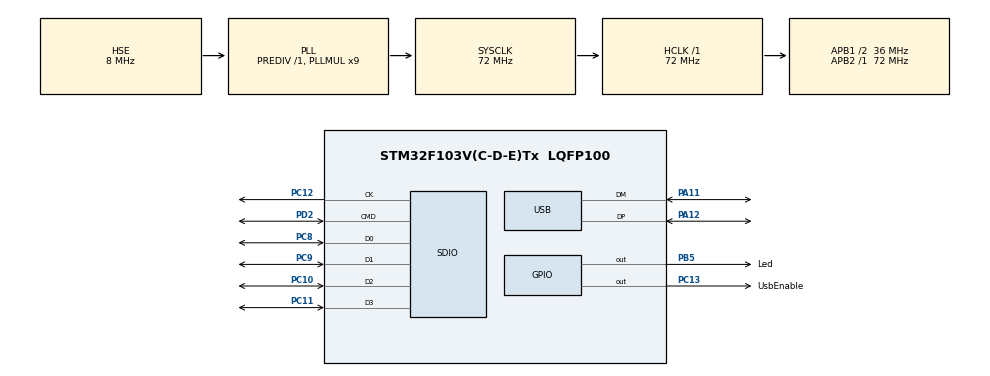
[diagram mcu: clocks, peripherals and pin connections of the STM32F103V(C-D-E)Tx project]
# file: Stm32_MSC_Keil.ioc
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Mcu.Family=STM32F1
Mcu.Name=STM32F103V(C-D-E)Tx
Mcu.Package=LQFP100
NVIC.PriorityGroup=NVIC_PRIORITYGROUP_4
NVIC.TIM1_UP_IRQn=true\:0\:0\:false\:false\:true\:false\:true
NVIC.TimeBase=TIM1_UP_IRQn
NVIC.TimeBaseIP=TIM1
NVIC.USB_LP_CAN1_RX0_IRQn=true\:0\:0\:false\:false\:true\:false\:true
OSC_IN.Mode=HSE-External-Oscillator
OSC_IN.Signal=RCC_OSC_IN
OSC_OUT.Mode=HSE-External-Oscillator
OSC_OUT.Signal=RCC_OSC_OUT
PA11.Mode=Device
PA11.Signal=USB_DM
PA12.Mode=Device
PA12.Signal=USB_DP
PB5.GPIO_Label=Led
PB5.Signal=GPIO_Output
PC10.Mode=SD_4_bits_Wide_bus
PC10.Signal=SDIO_D2
PC11.Mode=SD_4_bits_Wide_bus
PC11.Signal=SDIO_D3
PC12.Mode=SD_4_bits_Wide_bus
PC12.Signal=SDIO_CK
PC13-TAMPER-RTC.GPIO_Label=UsbEnable
PC13-TAMPER-RTC.Signal=GPIO_Output
PC14-OSC32_IN.Mode=LSE-External-Oscillator
PC14-OSC32_IN.Signal=RCC_OSC32_IN
PC15-OSC32_OUT.Mode=LSE-External-Oscillator
PC15-OSC32_OUT.Signal=RCC_OSC32_OUT
PC8.Mode=SD_4_bits_Wide_bus
PC8.Signal=SDIO_D0
PC9.Mode=SD_4_bits_Wide_bus
PC9.Signal=SDIO_D1
PD2.Mode=SD_4_bits_Wide_bus
PD2.Signal=SDIO_CMD
ProjectManager.HeapSize=0x2000
ProjectManager.StackSize=0x4000
ProjectManager.TargetToolchain=MDK-ARM V5
RCC.AHBFreq_Value=72000000
RCC.APB1CLKDivider=RCC_HCLK_DIV2
RCC.APB1Freq_Value=36000000
RCC.APB1TimFreq_Value=72000000
RCC.APB2Freq_Value=72000000
RCC.APB2TimFreq_Value=72000000
RCC.HCLKFreq_Value=72000000
RCC.PLLMUL=RCC_PLL_MUL9
RCC.SYSCLKFreq_VALUE=72000000
RCC.SYSCLKSource=RCC_SYSCLKSOURCE_PLLCLK
RCC.USBFreq_Value=48000000
RCC.USBPrescaler=RCC_USBCLKSOURCE_PLL_DIV1_5
SDIO.ClockDiv=4
USB_DEVICE.CLASS_NAME_FS=MSC
USB_DEVICE.VirtualMode=Msc
USB_DEVICE.VirtualModeFS=Msc_FS
VP_FATFS_VS_SDIO.Mode=SDIO
VP_SYS_VS_ND.Mode=No_Debug
VP_SYS_VS_tim1.Mode=TIM1
VP_USB_DEVICE_VS_USB_DEVICE_MSC_FS.Mode=MSC_FS
board=custom

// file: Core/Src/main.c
/* USER CODE BEGIN Header */
/**
  ******************************************************************************
  * @file           : main.c
  * @brief          : Main program body
  ******************************************************************************
  * @attention
  *
  * <h2><center>&copy; Copyright (c) 2019 STMicroelectronics.
  * All rights reserved.</center></h2>
  *
  * This software component is licensed by ST under Ultimate Liberty license
  * SLA0044, the "License"; You may not use this file except in compliance with
  * the License. You may obtain a copy of the License at:
  *                             www.st.com/SLA0044
  *
  ******************************************************************************
  */
/* USER CODE END Header */

#include "main.h"
#include "fatfs.h"
#include "sdio.h"
#include "usb_device.h"
#include "gpio.h"

void SystemClock_Config(void);

int main(void)
{

  /* MCU Configuration--------------------------------------------------------*/

  /* Reset of all peripherals, Initializes the Flash interface and the Systick. */
  HAL_Init();

  /* Configure the system clock */
  SystemClock_Config();

  /* Initialize all configured peripherals */
  MX_GPIO_Init();
  MX_SDIO_SD_Init();
  MX_FATFS_Init();
  MX_USB_DEVICE_Init();
  /* USER CODE BEGIN 2 */
	//if (SD_IAPUpdateReq()) {
	  //HAL_GPIO_WritePin(Led_GPIO_Port, Led_Pin, GPIO_PIN_SET);
	//}
  /* USER CODE END 2 */

  /* Infinite loop */
  while (1)
  {

  }
}

void SystemClock_Config(void)
{
  RCC_OscInitTypeDef RCC_OscInitStruct = {0};
  RCC_ClkInitTypeDef RCC_ClkInitStruct = {0};
  RCC_PeriphCLKInitTypeDef PeriphClkInit = {0};

  /** Initializes the CPU, AHB and APB busses clocks
  */
  RCC_OscInitStruct.OscillatorType = RCC_OSCILLATORTYPE_HSE;
  RCC_OscInitStruct.HSEState = RCC_HSE_ON;
  RCC_OscInitStruct.HSEPredivValue = RCC_HSE_PREDIV_DIV1;
  RCC_OscInitStruct.HSIState = RCC_HSI_ON;
  RCC_OscInitStruct.PLL.PLLState = RCC_PLL_ON;
  RCC_OscInitStruct.PLL.PLLSource = RCC_PLLSOURCE_HSE;
  RCC_OscInitStruct.PLL.PLLMUL = RCC_PLL_MUL9;
  if (HAL_RCC_OscConfig(&RCC_OscInitStruct) != HAL_OK)
  {
    Error_Handler();
  }
  /** Initializes the CPU, AHB and APB busses clocks
  */
  RCC_ClkInitStruct.ClockType = RCC_CLOCKTYPE_HCLK|RCC_CLOCKTYPE_SYSCLK
                              |RCC_CLOCKTYPE_PCLK1|RCC_CLOCKTYPE_PCLK2;
  RCC_ClkInitStruct.SYSCLKSource = RCC_SYSCLKSOURCE_PLLCLK;
  RCC_ClkInitStruct.AHBCLKDivider = RCC_SYSCLK_DIV1;
  RCC_ClkInitStruct.APB1CLKDivider = RCC_HCLK_DIV2;
  RCC_ClkInitStruct.APB2CLKDivider = RCC_HCLK_DIV1;

  if (HAL_RCC_ClockConfig(&RCC_ClkInitStruct, FLASH_LATENCY_2) != HAL_OK)
  {
    Error_Handler();
  }
  PeriphClkInit.PeriphClockSelection = RCC_PERIPHCLK_USB;
  PeriphClkInit.UsbClockSelection = RCC_USBCLKSOURCE_PLL_DIV1_5;
  if (HAL_RCCEx_PeriphCLKConfig(&PeriphClkInit) != HAL_OK)
  {
    Error_Handler();
  }
}

void HAL_TIM_PeriodElapsedCallback(TIM_HandleTypeDef *htim)
{
  if (htim->Instance == TIM1) {
    HAL_IncTick();
  }
}

void Error_Handler(void)
{
}

/************************ (C) COPYRIGHT STMicroelectronics *****END OF FILE****/
